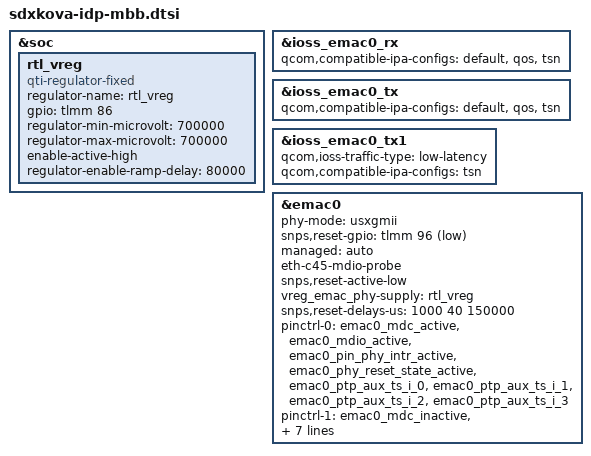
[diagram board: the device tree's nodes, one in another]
// SPDX-License-Identifier: BSD-3-Clause
/*
 * Copyright (c) 2024 Qualcomm Innovation Center, Inc. All rights reserved.
 */

#include "sdxkova.dtsi"

&soc {
	rtl_vreg: rtl_vreg {
		compatible = "qti-regulator-fixed";
		regulator-name = "rtl_vreg";
		gpio = <&tlmm 86 GPIO_ACTIVE_HIGH>;
		regulator-min-microvolt = <700000>;
		regulator-max-microvolt = <700000>;
		enable-active-high;
		regulator-enable-ramp-delay = <80000>;
	};
};

&ioss_emac0_rx {
	qcom,compatible-ipa-configs = "default", "qos", "tsn";
};

&ioss_emac0_tx {
	qcom,compatible-ipa-configs = "default", "qos", "tsn";
};

&ioss_emac0_tx1 {
	qcom,ioss-traffic-type = "low-latency";
	qcom,compatible-ipa-configs = "tsn";
};

&emac0 {
	status = "ok";
	phy-mode = "usxgmii";
	snps,reset-gpio = <&tlmm 96 1>;
	managed = "auto";
	eth-c45-mdio-probe;
	snps,reset-active-low;
	vreg_emac_phy-supply = <&rtl_vreg>;
	snps,reset-delays-us = <1000 40 150000>;

	pinctrl-0 = <&emac0_mdc_active
		     &emac0_mdio_active
		     &emac0_pin_phy_intr_active
		     &emac0_phy_reset_state_active
		     &emac0_ptp_aux_ts_i_0
		     &emac0_ptp_aux_ts_i_1
		     &emac0_ptp_aux_ts_i_2
		     &emac0_ptp_aux_ts_i_3>;
	pinctrl-1 = <&emac0_mdc_inactive
		     &emac0_mdio_inactive
		     &emac0_pin_phy_intr_inactive
		     &emac0_phy_reset_state_inactive
		     &emac0_ptp_aux_ts_i_0
		     &emac0_ptp_aux_ts_i_1
		     &emac0_ptp_aux_ts_i_2
		     &emac0_ptp_aux_ts_i_3>;

	eth_aux_ts_enabled;
	qcom,aux_ts_num_pins = <4>;
};
